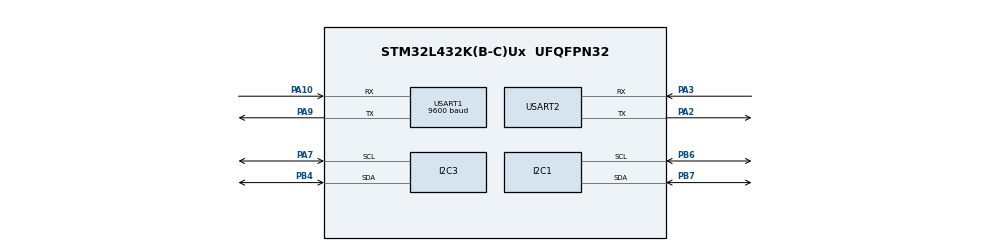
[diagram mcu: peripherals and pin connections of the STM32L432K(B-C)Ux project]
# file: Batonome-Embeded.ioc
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FREERTOS.Tasks01=defaultTask,24,128,StartDefaultTask,Default,NULL,Dynamic,NULL,NULL
Mcu.Family=STM32L4
Mcu.Name=STM32L432K(B-C)Ux
Mcu.Package=UFQFPN32
NVIC.PriorityGroup=NVIC_PRIORITYGROUP_4
NVIC.TIM6_DAC_IRQn=true\:15\:0\:false\:false\:true\:false\:false\:true\:true
NVIC.TimeBase=TIM6_DAC_IRQn
NVIC.TimeBaseIP=TIM6
NVIC.USART1_IRQn=true\:5\:0\:false\:false\:true\:true\:true\:true\:true
PA10.Mode=Asynchronous
PA10.Signal=USART1_RX
PA2.Mode=Asynchronous
PA2.Signal=USART2_TX
PA3.Mode=Asynchronous
PA3.Signal=USART2_RX
PA7.Mode=I2C
PA7.Signal=I2C3_SCL
PA9.Mode=Asynchronous
PA9.Signal=USART1_TX
PB4\ (NJTRST).Mode=I2C
PB4\ (NJTRST).Signal=I2C3_SDA
PB6.Mode=I2C
PB6.Signal=I2C1_SCL
PB7.Mode=I2C
PB7.Signal=I2C1_SDA
ProjectManager.HeapSize=0x200
ProjectManager.StackSize=0x400
ProjectManager.TargetToolchain=STM32CubeIDE
RCC.HSE_VALUE=8000000
RCC.HSI48_VALUE=48000000
RCC.HSI_VALUE=16000000
RCC.LSE_VALUE=32768
RCC.MSI_VALUE=4000000
RCC.VCOOutputFreq_Value=32000000
USART1.BaudRate=9600
USART1.VirtualMode-Asynchronous=VM_ASYNC
USART2.VirtualMode-Asynchronous=VM_ASYNC
VP_FREERTOS_VS_CMSIS_V2.Mode=CMSIS_V2
VP_SYS_VS_tim6.Mode=TIM6
board=custom

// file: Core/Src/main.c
/* USER CODE BEGIN Header */
/**
  ******************************************************************************
  * @file           : main.c
  * @brief          : Main program body
  ******************************************************************************
  * @attention
  *
  * Copyright (c) 2023 STMicroelectronics.
  * All rights reserved.
  *
  * This software is licensed under terms that can be found in the LICENSE file
  * in the root directory of this software component.
  * If no LICENSE file comes with this software, it is provided AS-IS.
  *
  ******************************************************************************
  */
/* USER CODE END Header */
#include "main.h"
#include "cmsis_os.h"

/* USER CODE BEGIN Includes */
#include <stdio.h>
/* USER CODE END Includes */

I2C_HandleTypeDef hi2c1;
I2C_HandleTypeDef hi2c3;

UART_HandleTypeDef huart1;
UART_HandleTypeDef huart2;

/* Definitions for defaultTask */
osThreadId_t defaultTaskHandle;
const osThreadAttr_t defaultTask_attributes = {
  .name = "defaultTask",
  .stack_size = 128 * 4,
  .priority = (osPriority_t) osPriorityNormal,
};

void SystemClock_Config(void);
static void MX_GPIO_Init(void);
static void MX_USART1_UART_Init(void);
static void MX_USART2_UART_Init(void);
static void MX_I2C1_Init(void);
static void MX_I2C3_Init(void);
void StartDefaultTask(void *argument);

/* USER CODE BEGIN 0 */
#ifdef __GNUC__
#define PUTCHAR_PROTOTYPE int __io_putchar(int ch)
#else
#define PUTCHAR_PROTOTYPE int fputc(int ch, FILE *f)
#endif

PUTCHAR_PROTOTYPE
{
  HAL_UART_Transmit(&huart2, (uint8_t *)&ch, 1, HAL_MAX_DELAY);
  return ch;
}
/* USER CODE END 0 */

int main(void)
{

  /* MCU Configuration--------------------------------------------------------*/

  /* Reset of all peripherals, Initializes the Flash interface and the Systick. */
  HAL_Init();

  /* Configure the system clock */
  SystemClock_Config();

  /* Initialize all configured peripherals */
  MX_GPIO_Init();
  MX_USART1_UART_Init();
  MX_USART2_UART_Init();
  MX_I2C1_Init();
  MX_I2C3_Init();
  /* USER CODE BEGIN 2 */

  printf("Welcome BATONOME V1.0.0\n");
  gps_Init();
  imu_Init();
  zigbee_Init();

  /* USER CODE END 2 */

  /* Init scheduler */
  osKernelInitialize();

  /* Create the thread(s) */
  /* creation of defaultTask */
  defaultTaskHandle = osThreadNew(StartDefaultTask, NULL, &defaultTask_attributes);

  /* Start scheduler */
  osKernelStart();

  /* We should never get here as control is now taken by the scheduler */
  /* Infinite loop */
  while (1)
  {

  }
}

void SystemClock_Config(void)
{
  RCC_OscInitTypeDef RCC_OscInitStruct = {0};
  RCC_ClkInitTypeDef RCC_ClkInitStruct = {0};

  /** Configure the main internal regulator output voltage
  */
  if (HAL_PWREx_ControlVoltageScaling(PWR_REGULATOR_VOLTAGE_SCALE1) != HAL_OK)
  {
    Error_Handler();
  }

  /** Initializes the RCC Oscillators according to the specified parameters
  * in the RCC_OscInitTypeDef structure.
  */
  RCC_OscInitStruct.OscillatorType = RCC_OSCILLATORTYPE_MSI;
  RCC_OscInitStruct.MSIState = RCC_MSI_ON;
  RCC_OscInitStruct.MSICalibrationValue = 0;
  RCC_OscInitStruct.MSIClockRange = RCC_MSIRANGE_6;
  RCC_OscInitStruct.PLL.PLLState = RCC_PLL_NONE;
  if (HAL_RCC_OscConfig(&RCC_OscInitStruct) != HAL_OK)
  {
    Error_Handler();
  }

  /** Initializes the CPU, AHB and APB buses clocks
  */
  RCC_ClkInitStruct.ClockType = RCC_CLOCKTYPE_HCLK|RCC_CLOCKTYPE_SYSCLK
                              |RCC_CLOCKTYPE_PCLK1|RCC_CLOCKTYPE_PCLK2;
  RCC_ClkInitStruct.SYSCLKSource = RCC_SYSCLKSOURCE_MSI;
  RCC_ClkInitStruct.AHBCLKDivider = RCC_SYSCLK_DIV1;
  RCC_ClkInitStruct.APB1CLKDivider = RCC_HCLK_DIV1;
  RCC_ClkInitStruct.APB2CLKDivider = RCC_HCLK_DIV1;

  if (HAL_RCC_ClockConfig(&RCC_ClkInitStruct, FLASH_LATENCY_0) != HAL_OK)
  {
    Error_Handler();
  }
}

static void MX_I2C1_Init(void)
{

  hi2c1.Instance = I2C1;
  hi2c1.Init.Timing = 0x00000E14;
  hi2c1.Init.OwnAddress1 = 0;
  hi2c1.Init.AddressingMode = I2C_ADDRESSINGMODE_7BIT;
  hi2c1.Init.DualAddressMode = I2C_DUALADDRESS_DISABLE;
  hi2c1.Init.OwnAddress2 = 0;
  hi2c1.Init.OwnAddress2Masks = I2C_OA2_NOMASK;
  hi2c1.Init.GeneralCallMode = I2C_GENERALCALL_DISABLE;
  hi2c1.Init.NoStretchMode = I2C_NOSTRETCH_DISABLE;
  if (HAL_I2C_Init(&hi2c1) != HAL_OK)
  {
    Error_Handler();
  }

  /** Configure Analogue filter
  */
  if (HAL_I2CEx_ConfigAnalogFilter(&hi2c1, I2C_ANALOGFILTER_ENABLE) != HAL_OK)
  {
    Error_Handler();
  }

  /** Configure Digital filter
  */
  if (HAL_I2CEx_ConfigDigitalFilter(&hi2c1, 0) != HAL_OK)
  {
    Error_Handler();
  }

}

static void MX_I2C3_Init(void)
{

  hi2c3.Instance = I2C3;
  hi2c3.Init.Timing = 0x00000E14;
  hi2c3.Init.OwnAddress1 = 0;
  hi2c3.Init.AddressingMode = I2C_ADDRESSINGMODE_7BIT;
  hi2c3.Init.DualAddressMode = I2C_DUALADDRESS_DISABLE;
  hi2c3.Init.OwnAddress2 = 0;
  hi2c3.Init.OwnAddress2Masks = I2C_OA2_NOMASK;
  hi2c3.Init.GeneralCallMode = I2C_GENERALCALL_DISABLE;
  hi2c3.Init.NoStretchMode = I2C_NOSTRETCH_DISABLE;
  if (HAL_I2C_Init(&hi2c3) != HAL_OK)
  {
    Error_Handler();
  }

  /** Configure Analogue filter
  */
  if (HAL_I2CEx_ConfigAnalogFilter(&hi2c3, I2C_ANALOGFILTER_ENABLE) != HAL_OK)
  {
    Error_Handler();
  }

  /** Configure Digital filter
  */
  if (HAL_I2CEx_ConfigDigitalFilter(&hi2c3, 0) != HAL_OK)
  {
    Error_Handler();
  }

}

static void MX_USART1_UART_Init(void)
{

  huart1.Instance = USART1;
  huart1.Init.BaudRate = 9600;
  huart1.Init.WordLength = UART_WORDLENGTH_8B;
  huart1.Init.StopBits = UART_STOPBITS_1;
  huart1.Init.Parity = UART_PARITY_NONE;
  huart1.Init.Mode = UART_MODE_TX_RX;
  huart1.Init.HwFlowCtl = UART_HWCONTROL_NONE;
  huart1.Init.OverSampling = UART_OVERSAMPLING_16;
  huart1.Init.OneBitSampling = UART_ONE_BIT_SAMPLE_DISABLE;
  huart1.AdvancedInit.AdvFeatureInit = UART_ADVFEATURE_NO_INIT;
  if (HAL_UART_Init(&huart1) != HAL_OK)
  {
    Error_Handler();
  }

}

static void MX_USART2_UART_Init(void)
{

  huart2.Instance = USART2;
  huart2.Init.BaudRate = 115200;
  huart2.Init.WordLength = UART_WORDLENGTH_8B;
  huart2.Init.StopBits = UART_STOPBITS_1;
  huart2.Init.Parity = UART_PARITY_NONE;
  huart2.Init.Mode = UART_MODE_TX_RX;
  huart2.Init.HwFlowCtl = UART_HWCONTROL_NONE;
  huart2.Init.OverSampling = UART_OVERSAMPLING_16;
  huart2.Init.OneBitSampling = UART_ONE_BIT_SAMPLE_DISABLE;
  huart2.AdvancedInit.AdvFeatureInit = UART_ADVFEATURE_NO_INIT;
  if (HAL_UART_Init(&huart2) != HAL_OK)
  {
    Error_Handler();
  }

}

static void MX_GPIO_Init(void)
{

  /* GPIO Ports Clock Enable */
  __HAL_RCC_GPIOA_CLK_ENABLE();
  __HAL_RCC_GPIOB_CLK_ENABLE();

}

void StartDefaultTask(void *argument)
{
  for(;;)
  {
    osDelay(1);
  }
}

void HAL_TIM_PeriodElapsedCallback(TIM_HandleTypeDef *htim)
{
  if (htim->Instance == TIM6) {
    HAL_IncTick();
  }
}

void Error_Handler(void)
{
  __disable_irq();
  while (1)
  {
  }
}
